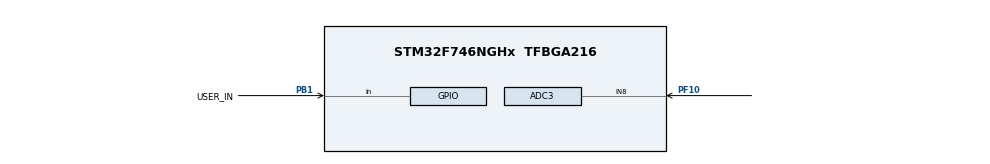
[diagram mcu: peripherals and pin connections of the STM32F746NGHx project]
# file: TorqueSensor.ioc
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ADC3.Channel-0\#ChannelRegularConversion=ADC_CHANNEL_8
ADC3.ContinuousConvMode=ENABLE
ADC3.NbrOfConversionFlag=1
ADC3.Rank-0\#ChannelRegularConversion=1
ADC3.SamplingTime-0\#ChannelRegularConversion=ADC_SAMPLETIME_3CYCLES
Mcu.Family=STM32F7
Mcu.Name=STM32F746NGHx
Mcu.Package=TFBGA216
NVIC.PriorityGroup=NVIC_PRIORITYGROUP_4
PB1.GPIO_Label=USER_IN
PB1.Signal=GPIO_Input
PF10.Mode=IN8
PF10.Signal=ADC3_IN8
ProjectManager.HeapSize=0x200
ProjectManager.StackSize=0x400
ProjectManager.TargetToolchain=STM32CubeIDE
RCC.HSE_VALUE=25000000
RCC.HSI_VALUE=16000000
RCC.LSE_VALUE=32768
RCC.USBFreq_Value=96000000
RCC.VCOOutputFreq_Value=192000000
board=custom

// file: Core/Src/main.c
/* USER CODE BEGIN Header */
/**
 ******************************************************************************
 * @file           : main.c
 * @brief          : Main program body
 ******************************************************************************
 * @attention
 *
 * Copyright (c) 2024 STMicroelectronics.
 * All rights reserved.
 *
 * This software is licensed under terms that can be found in the LICENSE file
 * in the root directory of this software component.
 * If no LICENSE file comes with this software, it is provided AS-IS.
 *
 ******************************************************************************
 */
/* USER CODE END Header */
#include "main.h"

/* USER CODE BEGIN PTD */
// Conversion factor for voltage to torque mapping
#define VOLTAGE_TO_TORQUE_FACTOR 0.17f
// Torque resolution based on ADC resolution (12 bits)
#define TORQUE_RESOLUTION 0.0244f
// Filter coefficient (adjust as needed)
#define FILTER_ALPHA 0.1f
#define ALPHA 0.1f

// Global variable
float torque_Value;
float torqueVoltage;
float voltage;
float filteredTorqueValue = 0.0f;  // Initialize the filtered torque value
uint32_t adcValue;
/* USER CODE END PTD */

ADC_HandleTypeDef hadc3;

void SystemClock_Config(void);
static void MX_GPIO_Init(void);
static void MX_ADC3_Init(void);

/* USER CODE BEGIN 0 */
float applyLowPassFilter(float rawValue, float previousFilteredValue) {
	  return (FILTER_ALPHA * rawValue) + ((1.0f - FILTER_ALPHA) * previousFilteredValue);
	}
/* USER CODE END 0 */

int main(void)
{

	/* MCU Configuration--------------------------------------------------------*/

	/* Reset of all peripherals, Initializes the Flash interface and the Systick. */
	HAL_Init();

	/* Configure the system clock */
	SystemClock_Config();

	/* Initialize all configured peripherals */
	MX_GPIO_Init();
	MX_ADC3_Init();
	/* USER CODE BEGIN 2 */

	// Declare adcValue variable here

		/* USER CODE END 2 */

		/* Infinite loop */
		/* USER CODE BEGIN WHILE */
		while (1)
		{
			// Start ADC conversion
			if (HAL_ADC_Start(&hadc3) != HAL_OK) {
				Error_Handler();
			}

			// Wait for conversion to complete
			if (HAL_ADC_PollForConversion(&hadc3, HAL_MAX_DELAY) != HAL_OK) {
				Error_Handler();
			}

			// Read ADC value
			 adcValue = HAL_ADC_GetValue(&hadc3);

			// Convert ADC value to voltage (assuming 3.3V reference voltage)
			 voltage = adcValue * (3.3f / 4096.0f);

			// Apply conversion factor to map voltage to torque sensor range
			 torqueVoltage = voltage * VOLTAGE_TO_TORQUE_FACTOR;

			filteredTorqueValue = applyLowPassFilter(torqueVoltage, filteredTorqueValue);
			// Calculate torque value based on the torque resolution
			 torque_Value = torqueVoltage * TORQUE_RESOLUTION  ;

			// Apply signal filtering techniques here if needed

			// Now 'torqueValue' contains the calculated torque value in Nm
		}
	}

	/* USER CODE END WHILE */

	/**
	 * @brief System Clock Configuration
	 * @retval None
	 */
	void SystemClock_Config(void)
	{
		RCC_OscInitTypeDef RCC_OscInitStruct = {0};
		RCC_ClkInitTypeDef RCC_ClkInitStruct = {0};

		/** Configure the main internal regulator output voltage
		 */
		__HAL_RCC_PWR_CLK_ENABLE();
		__HAL_PWR_VOLTAGESCALING_CONFIG(PWR_REGULATOR_VOLTAGE_SCALE3);

		/** Initializes the RCC Oscillators according to the specified parameters
		 * in the RCC_OscInitTypeDef structure.
		 */
		RCC_OscInitStruct.OscillatorType = RCC_OSCILLATORTYPE_HSI;
		RCC_OscInitStruct.HSIState = RCC_HSI_ON;
		RCC_OscInitStruct.HSICalibrationValue = RCC_HSICALIBRATION_DEFAULT;
		RCC_OscInitStruct.PLL.PLLState = RCC_PLL_NONE;
		if (HAL_RCC_OscConfig(&RCC_OscInitStruct) != HAL_OK)
		{
			Error_Handler();
		}

		/** Initializes the CPU, AHB and APB buses clocks
		 */
		RCC_ClkInitStruct.ClockType = RCC_CLOCKTYPE_HCLK|RCC_CLOCKTYPE_SYSCLK
				|RCC_CLOCKTYPE_PCLK1|RCC_CLOCKTYPE_PCLK2;
		RCC_ClkInitStruct.SYSCLKSource = RCC_SYSCLKSOURCE_HSI;
		RCC_ClkInitStruct.AHBCLKDivider = RCC_SYSCLK_DIV1;
		RCC_ClkInitStruct.APB1CLKDivider = RCC_HCLK_DIV1;
		RCC_ClkInitStruct.APB2CLKDivider = RCC_HCLK_DIV1;

		if (HAL_RCC_ClockConfig(&RCC_ClkInitStruct, FLASH_LATENCY_0) != HAL_OK)
		{
			Error_Handler();
		}
	}

	/**
	 * @brief ADC3 Initialization Function
	 * @param None
	 * @retval None
	 */
	static void MX_ADC3_Init(void)
	{

		ADC_ChannelConfTypeDef sConfig = {0};

		/** Configure the global features of the ADC (Clock, Resolution, Data Alignment and number of conversion)
		 */
		hadc3.Instance = ADC3;
		hadc3.Init.ClockPrescaler = ADC_CLOCK_SYNC_PCLK_DIV2;
		hadc3.Init.Resolution = ADC_RESOLUTION_12B;
		hadc3.Init.ScanConvMode = ADC_SCAN_DISABLE;
		hadc3.Init.ContinuousConvMode = ENABLE;
		hadc3.Init.DiscontinuousConvMode = DISABLE;
		hadc3.Init.ExternalTrigConvEdge = ADC_EXTERNALTRIGCONVEDGE_NONE;
		hadc3.Init.ExternalTrigConv = ADC_SOFTWARE_START;
		hadc3.Init.DataAlign = ADC_DATAALIGN_RIGHT;
		hadc3.Init.NbrOfConversion = 1;
		hadc3.Init.DMAContinuousRequests = DISABLE;
		hadc3.Init.EOCSelection = ADC_EOC_SINGLE_CONV;
		if (HAL_ADC_Init(&hadc3) != HAL_OK)
		{
			Error_Handler();
		}

		/** Configure for the selected ADC regular channel its corresponding rank in the sequencer and its sample time.
		 */
		sConfig.Channel = ADC_CHANNEL_8;
		sConfig.Rank = ADC_REGULAR_RANK_1;
		sConfig.SamplingTime = ADC_SAMPLETIME_3CYCLES;
		if (HAL_ADC_ConfigChannel(&hadc3, &sConfig) != HAL_OK)
		{
			Error_Handler();
		}

	}

	/**
	 * @brief GPIO Initialization Function
	 * @param None
	 * @retval None
	 */
	static void MX_GPIO_Init(void)
	{
		GPIO_InitTypeDef GPIO_InitStruct = {0};

		/* GPIO Ports Clock Enable */
		__HAL_RCC_GPIOF_CLK_ENABLE();
		__HAL_RCC_GPIOB_CLK_ENABLE();

		/*Configure GPIO pin : USER_IN_Pin */
		GPIO_InitStruct.Pin = USER_IN_Pin;
		GPIO_InitStruct.Mode = GPIO_MODE_INPUT;
		GPIO_InitStruct.Pull = GPIO_NOPULL;
		HAL_GPIO_Init(USER_IN_GPIO_Port, &GPIO_InitStruct);

	}

	/**
	 * @brief  This function is executed in case of error occurrence.
	 * @retval None
	 */
	void Error_Handler(void)
	{
		__disable_irq();
		while (1)
		{
		}
	}
